# MM32F3270 register map
File version: 3.01
CPU: CM3 r2p1, selectable endian, MPU, no FPU, 3 interrupt priority bits
Registers are 32-bit, read-write, reset 0x0 unless marked. A register's access mark holds for its fields unless they carry their own. Offsets are from the block's base; [hi:lo] are bit positions; {n}, {i} and the like mark numbered series.

## RCC — Reset and clock control
Base 0x40021000
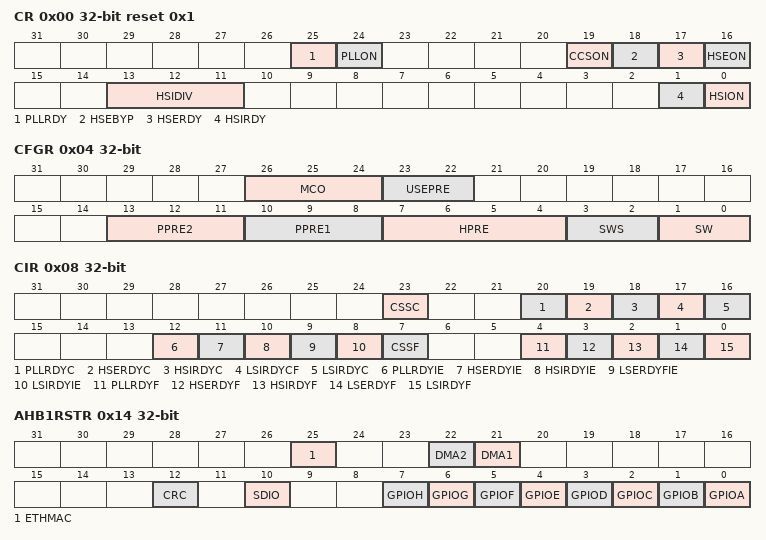
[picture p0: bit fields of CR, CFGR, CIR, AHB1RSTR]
0x00 CR reset 0x1 — Control Register
  [25] PLLRDY — PLL clock ready flag
  [24] PLLON — PLL enable
  [19] CCSON — lock security system enable
  [18] HSEBYP — External high-speed clock bypass
  [17] HSERDY — External high-speed clock ready flag
  [16] HSEON — External high-speed clock enable
  [13:11] HSIDIV — Internal high-speed clock division factor
  [1] HSIRDY — Internal high-speed clock ready flag
  [0] HSION — Internal high-speed clock enable
0x04 CFGR — Configuration Register
  [26:24] MCO — Microcontroller clock output
  [23:22] USEPRE — USB prescaler
  [13:11] PPRE2 — APB low-speed prescaler(APB2)
  [10:8] PPRE1 — APB low-speed prescaler(APB1)
  [7:4] HPRE — AHB Prescaler
  [3:2] SWS — System clock switch status
  [1:0] SW — System clock switch
0x08 CIR — Clock Interrupt Register
  [23] CSSC write-1-clears — Clock security system interrupt clear
  [20] PLLRDYC write-1-clears — *D20
  [19] HSERDYC write-1-clears — HSE ready interrupt clear
  [18] HSIRDYC write-1-clears — HSI ready interrupt clear
  [17] LSIRDYCF write-1-clears — *D17
  [16] LSIRDYC write-1-clears — LSI ready interrupt clear
  [12] PLLRDYIE — *D12
  [11] HSERDYIE — HSE ready interrupt enable
  [10] HSIRDYIE — HSI ready interrupt enable
  [9] LSERDYFIE — *D9
  [8] LSIRDYIE — LSI ready interrupt enable
  [7] CSSF — Clock security system interrupt flag
  [4] PLLRDYF — *D4
  [3] HSERDYF — HSE ready interrupt flag
  [2] HSIRDYF — HSI ready interrupt flag
  [1] LSERDYF — *D1
  [0] LSIRDYF — LSI ready interrupt flag
0x0C AHB3RSTR — Advanced High Performance Bus 3 Reset Register
  [0] FSMC — *D0
0x10 AHB2RSTR — Advanced High Performance Bus 2 Reset Register
  [7] USBOTGFS — *D7
0x14 AHB1RSTR — Advanced High Performance Bus 1 Reset Register
  [25] ETHMAC — ETHMAC reset
  [22] DMA2 — DMA2 reset
  [21] DMA1 — DMA1 reset
  [12] CRC — *12
  [10] SDIO — SDIO reset
  [7] GPIOH — USBOTGFS reset
  [6] GPIOG — GPIOG reset
  [5] GPIOF — GPIOF reset
  [4] GPIOE — GPIOE reset
  [3] GPIOD — GPIOD reset
  [2] GPIOC — GPIOC reset
  [1] GPIOB — GPIOb reset
  [0] GPIOA — FSMC reset
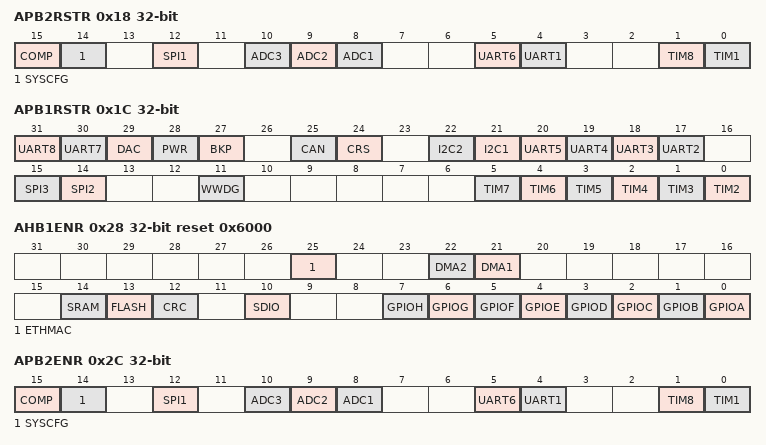
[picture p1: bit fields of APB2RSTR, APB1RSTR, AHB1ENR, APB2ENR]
0x18 APB2RSTR — Advanced Peripheral Bus 2 Reset Register
  [15] COMP — COMP reset
  [14] SYSCFG — SYSCFG reset
  [12] SPI1 — SPI1 reset
  [10] ADC3 — ADC3 reset
  [9] ADC2 — ADC2 reset
  [8] ADC1 — ADC1 reset
  [5] UART6 — UART6 reset
  [4] UART1 — UART1 reset
  [1] TIM8 — TIM8 timer reset
  [0] TIM1 — TIM1 timer reset
0x1C APB1RSTR — Advanced Peripheral Bus 1 Reset Register
  [31] UART8 — UART8 reset
  [30] UART7 — UART7 reset
  [29] DAC — DAC reset
  [28] PWR — Power interface reset
  [27] BKP — Backup interface reset
  [25] CAN — CAN reset
  [24] CRS — CRS reset
  [22] I2C2 — I2C2 reset
  [21] I2C1 — I2C1 reset
  [n+15] UART{n} (n=2..5) — UART{n} reset
  [15] SPI3 — SPI3 reset
  [14] SPI2 — SPI2 reset
  [11] WWDG — Window watchdog reset
  [n-2] TIM{n} (n=2..7) — TIM{n} reset
0x20 AHB3ENR — Advanced High Performance Bus 3 Enable Register
  [0] FSMC — *D0
0x24 AHB2ENR — Advanced High Performance Bus 2 Enable Register
  [7] USBOTGFS — *D7
0x28 AHB1ENR reset 0x6000 — Advanced High Performance Bus 1 Enable Register
  [25] ETHMAC — ETHMAC clock enable
  [22] DMA2 — DMA2 clock enable
  [21] DMA1 — DMA1 clock enable
  [14] SRAM — *14
  [13] FLASH — *13
  [12] CRC — *12
  [10] SDIO — SDIO clock enable
  [7] GPIOH — USBOTGFS clock enable
  [6] GPIOG — GPIOG clock enable
  [5] GPIOF — GPIOF clock enable
  [4] GPIOE — GPIOE clock enable
  [3] GPIOD — GPIOD clock enable
  [2] GPIOC — GPIOC clock enable
  [1] GPIOB — GPIOb clock enable
  [0] GPIOA — FSMC clock enable
0x2C APB2ENR — Advanced Peripheral Bus 2 Enable Register
  [15] COMP — COMP clock enable
  [14] SYSCFG — SYSCFG clock enable
  [12] SPI1 — SPI1 clock enable
  [10] ADC3 — ADC3 clock enable
  [9] ADC2 — ADC2 clock enable
  [8] ADC1 — ADC1 clock enable
  [5] UART6 — UART6 clock enable
  [4] UART1 — UART1 clock enable
  [1] TIM8 — TIM8 timer clock enable
  [0] TIM1 — TIM1 timer clock enable
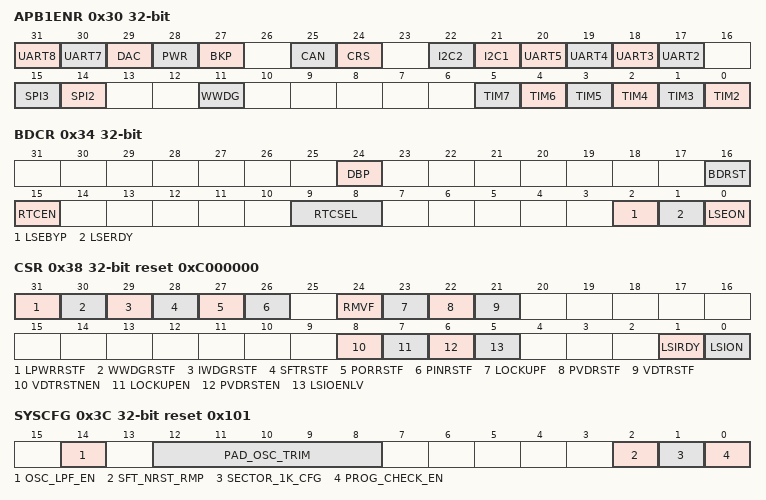
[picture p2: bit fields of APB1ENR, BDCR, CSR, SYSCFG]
0x30 APB1ENR — Advanced Peripheral Bus 1 Enable Register
  [31] UART8 — UART8 clock enable
  [30] UART7 — UART7 clock enable
  [29] DAC — DAC clock enable
  [28] PWR — Power interface clock enable
  [27] BKP — Backup interface clock enable
  [25] CAN — CAN clock enable
  [24] CRS — CRS clock enable
  [22] I2C2 — I2C2 clock enable
  [21] I2C1 — I2C1 clock enable
  [n+15] UART{n} (n=2..5) — UART{n} clock enable
  [15] SPI3 — SPI3 clock enable
  [14] SPI2 — SPI2 clock enable
  [11] WWDG — Window watchdog clock enable
  [n-2] TIM{n} (n=2..7) — TIM{n} clock enable
0x34 BDCR — Backup Domain Control Register
  [24] DBP — Cancel Backup domain Write protection
  [16] BDRST — Backup domain software reset
  [15] RTCEN — RTC clock enable
  [9:8] RTCSEL — RTC clock source selection
  [2] LSEBYP — External low-speed oscillator bypass
  [1] LSERDY ro — External low-speed oscillator ready
  [0] LSEON — External low-speed oscillator enable
0x38 CSR reset 0xC000000 — Control Status Register
  [31] LPWRRSTF ro — *D31
  [30] WWDGRSTF ro — Window watchdog reset flag
  [29] IWDGRSTF ro — Independent watchdog reset flag
  [28] SFTRSTF ro — Software reset flag
  [27] PORRSTF ro — POR/PDR reset flag
  [26] PINRSTF ro — PIN reset flag
  [24] RMVF wo — Remove reset flag
  [23] LOCKUPF ro — CPU lockup reset flag
  [22] PVDRSTF ro — PVD reset flag
  [21] VDTRSTF ro — Voltage detect reset flag
  [8] VDTRSTNEN — Voltage detect reset enable
  [7] LOCKUPEN — CPU lockup reset enable
  [6] PVDRSTEN — PVD reset enable
  [5] LSIOENLV — LSI output enable lower voltage
  [1] LSIRDY ro — Internal low-speed oscillator ready
  [0] LSION — Internal low-speed oscillator enable
0x3C SYSCFG reset 0x101 — System Configuration Register
  [14] OSC_LPF_EN — External crystal low-pass filter enable
  [12:8] PAD_OSC_TRIM — Calibration of external crystal oscillator
  [2] SFT_NRST_RMP — Software mapping NRST
  [1] SECTOR_1K_CFG — The size of flash page erase
  [0] PROG_CHECK_EN — Whether to check if the data in Flash is 0xFF when writing Flash
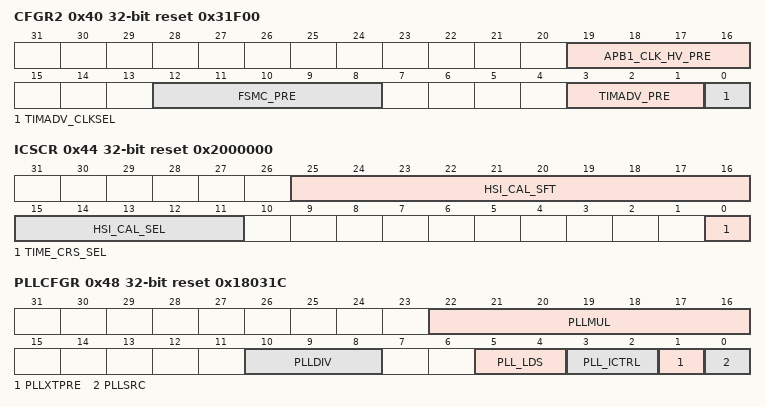
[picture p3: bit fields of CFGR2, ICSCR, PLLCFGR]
0x40 CFGR2 reset 0x31F00 — Configure Register 2
  [19:16] APB1_CLK_HV_PRE — FSMC_PRE clock Frequency division coefficient
  [12:8] FSMC_PRE — *D8
  [3:1] TIMADV_PRE — SYSCLK clock Frequency division coefficient
  [0] TIMADV_CLKSEL — TIMADV clock selection
0x44 ICSCR reset 0x2000000 — Internal clock sourcec Configure Register
  [25:16] HSI_CAL_SFT — Internal high-speed clock calibration
  [15:11] HSI_CAL_SEL — Initial value of internal high-speed clock calibration
  [0] TIME_CRS_SEL — CRS module flag
0x48 PLLCFGR reset 0x18031C — PLL Configure Register
  [22:16] PLLMUL — PLL multiplication factor
  [10:8] PLLDIV — PLL divide factor
  [5:4] PLL_LDS — PLL lock detector accuracy select
  [3:2] PLL_ICTRL — PLL CP current control signals
  [1] PLLXTPRE — HSE divider for PLL entry
  [0] PLLSRC — PLL entry clock source
0x80 HSIDLY reset 0x1E — HSI Delay Register
  [7:0] HSI_EQU_CNT — *D0
0x84 HSEDLY reset 0xBB80 — HSE Delay Register
  [15:0] HSE_EQU_CNT — *D0
0x88 PLLDLY reset 0x3EB — PLL Delay Register
  [7:0] PLL_EQU_CNT — *D0
